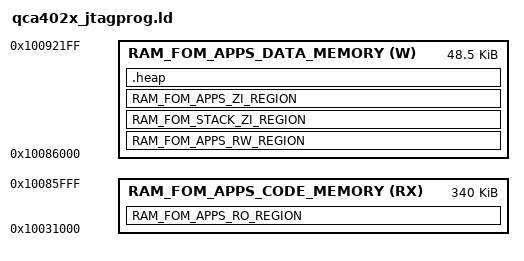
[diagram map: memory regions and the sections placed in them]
/**********
 * This file was generated by a tool.
 *    Tool name     : MakeLinkerScript.py
 *    Template file : DefaultTemplateLinkerScript.ld
 *    Placement file: app.placement
 *    Placement file: LinkerLibs.txt
 *
 * Do not modify this file directly.
 * Rather, change the template, the placement file or the tool.
 *********/

/* RAM_START  = 0x10000000; */
/* RAM_LENGTH = 0x000B8000; */
/* XIP_START  = 0x10100000; */
/* XIP_LENGTH = 0x00080000; */

MEMORY
{
 RAM_FOM_APPS_CODE_MEMORY                          (RX) : ORIGIN = 0x10031000, LENGTH = 0x55000
 RAM_FOM_APPS_DATA_MEMORY                          (W)  : ORIGIN = 0x10086000, LENGTH = 0xC200
}

PHDRS
{
   RAM_FOM_APPS_CODE_SEGMENT     PT_LOAD;
   RAM_FOM_APPS_DATA_SEGMENT     PT_LOAD;
}

SECTIONS
{
    RAM_FOM_APPS_RO_REGION : 
    {
		*(.text)
		*(.text.*)
		*(.ARM.Collect*)
		*(.rodata)
		*flash_init_config.o(.text)
		*(.rodata.str1.4)
    } >RAM_FOM_APPS_CODE_MEMORY : RAM_FOM_APPS_CODE_SEGMENT

    RAM_FOM_APPS_RW_REGION : 
    {
	    *(.data)
		*(JTAGPROG_DATA)
		*(RAM_FOM_BSP_RW_SECTION)
    } >RAM_FOM_APPS_DATA_MEMORY : RAM_FOM_APPS_DATA_SEGMENT
	
    RAM_FOM_STACK_ZI_REGION :
    {
		*/JtagProgrammer_stack.o(.bss)
		*/JtagProgrammer_stack.o(COMMON)
    } >RAM_FOM_APPS_DATA_MEMORY : RAM_FOM_APPS_DATA_SEGMENT
	
    RAM_FOM_APPS_ZI_REGION : 
    {
        _RAM_FOM_APPS_ZI_START = .;
		*(.bss)
        *(RAM_FOM_APPS_ZI_REGION)
        _RAM_FOM_APPS_ZI_END = ALIGN(0x100);      
    } >RAM_FOM_APPS_DATA_MEMORY : RAM_FOM_APPS_DATA_SEGMENT
	
	.heap : {
       __heap_start__ = .;
       end = __heap_start__;
       _end = end;
       __end = end;
       KEEP(*(.heap))
       __heap_end__ = .;
       __HeapLimit = __heap_end__;
    } >RAM_FOM_APPS_DATA_MEMORY
}

Image$$RAM_FOM_APPS_ZI_REGION$$ZI$$Base          = _RAM_FOM_APPS_ZI_START;
Load$$RAM_FOM_APPS_ZI_REGION$$ZI$$Base           = _RAM_FOM_APPS_ZI_START;
Image$$RAM_FOM_APPS_ZI_REGION$$ZI$$Length        = _RAM_FOM_APPS_ZI_END - _RAM_FOM_APPS_ZI_START;

